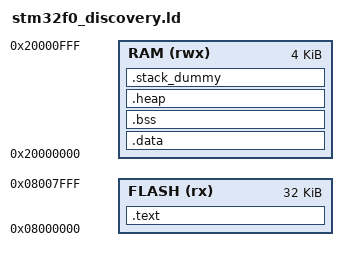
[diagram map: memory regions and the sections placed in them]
/* Linker script to configure memory regions. */
MEMORY
{
  FLASH (rx)  : ORIGIN = 0x08000000, LENGTH = 32K
  RAM   (rwx) : ORIGIN = 0x20000000, LENGTH = 4K
}

ENTRY(Reset_Handler)

SECTIONS
{
	.text :
	{
		KEEP(*(.vectors))
		__Vectors_End = .;
		__Vectors_Size = __Vectors_End - __Vectors;
		__end__ = .;

		*(.text*)

		KEEP(*(.init))
		KEEP(*(.fini))

		*(.rodata*)

		KEEP(*(.eh_frame*))
	} > FLASH

	.data :
	{
		__data_start__ = .;
		*(vtable)
		*(.data*)
		__data_end__ = .;

	} > RAM

	.bss :
	{
		. = ALIGN(4);
		__bss_start__ = .;
		*(.bss*)
		*(COMMON)
		. = ALIGN(4);
		__bss_end__ = .;
	} > RAM

	.heap (COPY):
	{
		__HeapBase = .;
		__end__ = .;
		end = __end__;
		KEEP(*(.heap*))
		__HeapLimit = .;
	} > RAM

	/* .stack_dummy section doesn't contains any symbols. It is only
	 * used for linker to calculate size of stack sections, and assign
	 * values to stack symbols later */
	.stack_dummy (COPY):
	{
		KEEP(*(.stack*))
	} > RAM

	/* Set stack top to end of RAM, and stack limit move down by
	 * size of stack_dummy section */
	__StackTop = ORIGIN(RAM) + LENGTH(RAM);
	__StackLimit = __StackTop - SIZEOF(.stack_dummy);
	PROVIDE(__stack = __StackTop);

	/* Check if data + heap + stack exceeds RAM limit */
	ASSERT(__StackLimit >= __HeapLimit, "region RAM overflowed with stack")
}
